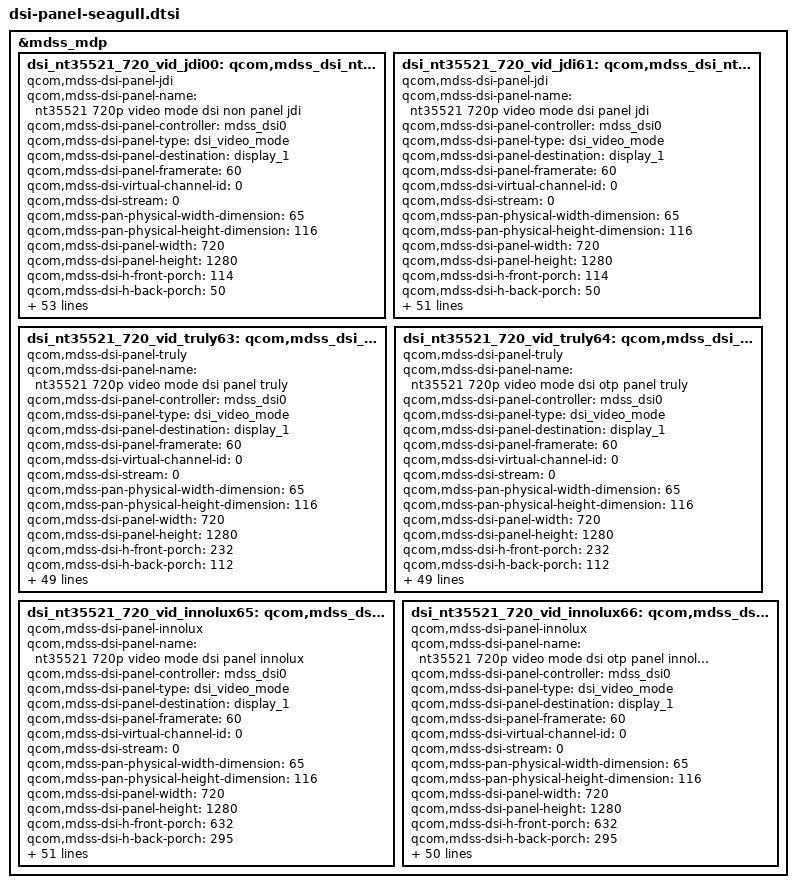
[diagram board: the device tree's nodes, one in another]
/* Copyright (c) 2013, The Linux Foundation. All rights reserved.
 *
 * This program is free software; you can redistribute it and/or modify
 * it under the terms of the GNU General Public License version 2 and
 * only version 2 as published by the Free Software Foundation.
 *
 * This program is distributed in the hope that it will be useful,
 * but WITHOUT ANY WARRANTY; without even the implied warranty of
 * MERCHANTABILITY or FITNESS FOR A PARTICULAR PURPOSE.  See the
 * GNU General Public License for more details.
 */

/*---------------------------------------------------------------------------
 * This file is autogenerated file using gcdb parser. Please do not edit it.
 * Update input XML file to add a new entry or update variable in this file
 * VERSION = "1.0"
 *---------------------------------------------------------------------------*/
&mdss_mdp {
	dsi_nt35521_720_vid_jdi00: qcom,mdss_dsi_nt35521_720p_video_jdi00 {
		compatible = "qcom,mdss-dsi-panel-jdi";
		qcom,mdss-dsi-panel-name = "nt35521 720p video mode dsi non panel jdi";
		qcom,mdss-dsi-panel-controller = <&mdss_dsi0>;
		qcom,mdss-dsi-panel-type = "dsi_video_mode";
		qcom,mdss-dsi-panel-destination = "display_1";
		qcom,mdss-dsi-panel-framerate = <60>;
		qcom,mdss-dsi-virtual-channel-id = <0>;
		qcom,mdss-dsi-stream = <0>;
		qcom,mdss-pan-physical-width-dimension = <65>;
		qcom,mdss-pan-physical-height-dimension = <116>;
		qcom,mdss-dsi-panel-width = <720>;
		qcom,mdss-dsi-panel-height = <1280>;
		qcom,mdss-dsi-h-front-porch = <114>;
		qcom,mdss-dsi-h-back-porch = <50>;
		qcom,mdss-dsi-h-pulse-width = <10>;
		qcom,mdss-dsi-h-sync-skew = <0>;
		qcom,mdss-dsi-v-back-porch = <10>;
		qcom,mdss-dsi-v-front-porch = <13>;
		qcom,mdss-dsi-v-pulse-width = <1>;
		qcom,mdss-dsi-h-left-border = <0>;
		qcom,mdss-dsi-h-right-border = <0>;
		qcom,mdss-dsi-v-top-border = <0>;
		qcom,mdss-dsi-v-bottom-border = <0>;
		qcom,mdss-dsi-bpp = <24>;
		qcom,mdss-dsi-color-order = <0>;
		qcom,mdss-dsi-underflow-color = <0xff>;
		qcom,mdss-dsi-border-color = <0>;
		qcom,mdss-dsi-pixel-packing = <0>;
		somc,mdss-dsi-id-read-command = [06 01 00 01 05 00 02 A1 00];
		qcom,mdss-dsi-on-command = [
				29 01 00 00 00 00 06 F0 55 AA 52 08 00
				23 01 00 00 00 00 02 B6 14
				29 01 00 00 00 00 05 B8 00 00 14 0A
				23 01 00 00 00 00 02 BA 00
				29 01 00 00 00 00 03 BB 63 63
				29 01 00 00 00 00 06 BD 02 7F 0D 0B 00
				29 01 00 00 00 00 04 D9 00 02 00
				29 01 00 00 00 00 06 F0 55 AA 52 00 00

				29 01 00 00 00 00 06 F0 55 AA 52 08 01
				29 01 00 00 00 00 03 B0 0D 0D
				29 01 00 00 00 00 03 B1 0D 0D
				29 01 00 00 00 00 03 B3 30 30
				29 01 00 00 00 00 03 B4 1B 1B
				29 01 00 00 00 00 03 B6 05 05
				29 01 00 00 00 00 03 B7 05 05
				29 01 00 00 00 00 03 B8 05 05
				29 01 00 00 00 00 03 B9 45 45
				29 01 00 00 00 00 03 BA 36 36
				29 01 00 00 00 00 03 BC 50 00
				29 01 00 00 00 00 03 BD 50 00
				23 01 00 00 00 00 02 BE 80
				23 01 00 00 00 00 02 BF 80
				23 01 00 00 00 00 02 C1 01
				29 01 00 00 00 00 04 C7 61 00 00
				23 01 00 00 00 00 02 CA 00
				29 01 00 00 00 00 04 CF 00 50 50
				29 01 00 00 00 00 06 F0 55 AA 52 00 00

				29 01 00 00 00 00 06 F0 55 AA 52 08 02
				29 01 00 00 00 00 11 B0 00 00 00 0F 00 29 00 3D 00 50 00 6F 00 8A 00 B6
				29 01 00 00 00 00 11 B1 00 DC 01 17 01 47 01 90 01 CB 01 CD 02 02 02 3E
				29 01 00 00 00 00 11 B2 02 71 02 B8 02 EC 03 37 03 6A 03 87 03 A0 03 A2
				29 01 00 00 00 00 05 B3 03 B6 03 CC
				29 01 00 00 00 00 11 B4 00 00 00 0F 00 29 00 3D 00 50 00 6F 00 8A 00 B6
				29 01 00 00 00 00 11 B5 00 DC 01 17 01 47 01 90 01 CB 01 CD 02 02 02 3E
				29 01 00 00 00 00 11 B6 02 71 02 B8 02 EC 03 37 03 6A 03 87 03 A0 03 A2
				29 01 00 00 00 00 05 B7 03 B6 03 CC

				29 01 00 00 00 00 11 B8 00 00 00 0F 00 29 00 3D 00 50 00 6F 00 8A 00 B6
				29 01 00 00 00 00 11 B9 00 DC 01 17 01 47 01 90 01 CB 01 CD 02 02 02 3E
				29 01 00 00 00 00 11 BA 02 71 02 B8 02 EC 03 37 03 6A 03 87 03 A0 03 A2
				29 01 00 00 00 00 05 BB 03 B6 03 CC
				29 01 00 00 00 00 11 BC 00 00 00 0F 00 29 00 3D 00 50 00 6F 00 8A 00 B6
				29 01 00 00 00 00 11 BD 00 DC 01 17 01 47 01 90 01 CB 01 CD 02 02 02 3E
				29 01 00 00 00 00 11 BE 02 71 02 B8 02 EC 03 37 03 6A 03 87 03 A0 03 A2
				29 01 00 00 00 00 05 BF 03 B7 03 CC

				29 01 00 00 00 00 11 C0 00 00 00 0F 00 29 00 3D 00 50 00 6F 00 8A 00 B6
				29 01 00 00 00 00 11 C1 00 DC 01 17 01 47 01 90 01 CB 01 CD 02 02 02 3E
				29 01 00 00 00 00 11 C2 02 71 02 B8 02 EC 03 37 03 6A 03 87 03 A0 03 A2
				29 01 00 00 00 00 05 C3 03 B6 03 CC
				29 01 00 00 00 00 11 C4 00 00 00 0F 00 29 00 3D 00 50 00 6F 00 8A 00 B6
				29 01 00 00 00 00 11 C5 00 DC 01 17 01 47 01 90 01 CB 01 CD 02 02 02 3E
				29 01 00 00 00 00 11 C6 02 71 02 B8 02 EC 03 37 03 6A 03 87 03 A0 03 A2
				29 01 00 00 00 00 05 C7 03 B6 03 CC
				23 01 00 00 00 00 02 EE 00
				29 01 00 00 00 00 06 F0 55 AA 52 00 00

				29 01 00 00 00 00 06 F0 55 AA 52 08 03
				29 01 00 00 00 00 03 B0 F5 00
				29 01 00 00 00 00 03 B1 F5 00
				29 01 00 00 00 00 06 B2 03 00 4C 00 01
				29 01 00 00 00 00 06 B6 03 00 4C 00 01
				29 01 00 00 00 00 06 BA 35 00 4C 00 01
				29 01 00 00 00 00 06 BB 35 00 4C 00 01
				29 01 00 00 00 00 05 C0 30 00 00 00
				29 01 00 00 00 00 05 C1 30 00 00 00
				29 01 00 00 00 00 05 C2 12 00 00 00
				29 01 00 00 00 00 05 C3 21 00 00 00
				23 01 00 00 00 00 02 C4 40
				29 01 00 00 00 00 06 F0 55 AA 52 00 00

				29 01 00 00 00 00 06 F0 55 AA 52 08 05
				29 01 00 00 00 00 03 B3 17 26
				29 01 00 00 00 00 03 B7 17 26
				29 01 00 00 00 00 06 BD 03 01 01 0F 0F
				23 01 00 00 00 00 02 C0 03
				23 01 00 00 00 00 02 C4 A6
				29 01 00 00 00 00 03 C8 05 30
				29 01 00 00 00 00 03 C9 01 11
				29 01 00 00 00 00 04 CC 00 00 04
				29 01 00 00 00 00 04 CD 00 00 04
				29 01 00 00 00 00 04 CE 00 00 04
				29 01 00 00 00 00 04 CF 00 00 04
				23 01 00 00 00 00 02 D0 00
				29 01 00 00 00 00 05 D1 02 00 00 04
				29 01 00 00 00 00 05 D2 02 00 00 02
				23 01 00 00 00 00 02 E5 06
				23 01 00 00 00 00 02 E6 06
				23 01 00 00 00 00 02 E7 06
				23 01 00 00 00 00 02 E8 06
				23 01 00 00 00 00 02 EC 06
				29 01 00 00 00 00 06 F0 55 AA 52 00 00

				29 01 00 00 00 00 06 F0 55 AA 52 08 06
				29 01 00 00 00 00 03 B0 2E 00
				29 01 00 00 00 00 03 B1 08 10
				29 01 00 00 00 00 03 B2 12 14
				29 01 00 00 00 00 03 B3 16 31
				29 01 00 00 00 00 03 B4 31 31
				29 01 00 00 00 00 03 B5 31 31
				29 01 00 00 00 00 03 B6 31 34
				29 01 00 00 00 00 03 B7 2B 2A
				29 01 00 00 00 00 03 B8 34 2C
				29 01 00 00 00 00 03 B9 29 34
				29 01 00 00 00 00 03 BA 34 29
				29 01 00 00 00 00 03 BB 2C 34
				29 01 00 00 00 00 03 BC 2A 2B
				29 01 00 00 00 00 03 BD 34 31
				29 01 00 00 00 00 03 BE 31 31
				29 01 00 00 00 00 03 BF 31 31
				29 01 00 00 00 00 03 C0 31 17
				29 01 00 00 00 00 03 C1 15 13
				29 01 00 00 00 00 03 C2 11 09
				29 01 00 00 00 00 03 C3 01 2E

				29 01 00 00 00 00 03 C4 2E 2D
				29 01 00 00 00 00 03 C5 01 17
				29 01 00 00 00 00 03 C6 15 13
				29 01 00 00 00 00 03 C7 11 31
				29 01 00 00 00 00 03 C8 31 31
				29 01 00 00 00 00 03 C9 31 31
				29 01 00 00 00 00 03 CA 31 34
				29 01 00 00 00 00 03 CB 2B 2A
				29 01 00 00 00 00 03 CC 34 2C
				29 01 00 00 00 00 03 CD 29 34
				29 01 00 00 00 00 03 CE 34 29
				29 01 00 00 00 00 03 CF 2C 34
				29 01 00 00 00 00 03 D0 2A 2B
				29 01 00 00 00 00 03 D1 34 31
				29 01 00 00 00 00 03 D2 31 31
				29 01 00 00 00 00 03 D3 31 31
				29 01 00 00 00 00 03 D4 31 10
				29 01 00 00 00 00 03 D5 12 14
				29 01 00 00 00 00 03 D6 16 00
				29 01 00 00 00 00 03 D7 2D 2E

				29 01 00 00 00 00 06 D8 00 00 00 00 00
				29 01 00 00 00 00 06 D9 00 00 00 00 00
				29 01 00 00 00 00 03 E5 34 34
				29 01 00 00 00 00 03 E6 34 34
				23 01 00 00 00 00 02 E7 00
				29 01 00 00 00 00 06 F0 55 AA 52 00 00

				//Modify backlight leds's freq to 65.1kHz
				29 01 00 00 00 00 06 F0 55 AA 52 08 00
				29 01 00 00 00 00 04 D9 02 03 00
				29 01 00 00 00 00 06 F0 55 AA 52 00 00

				/*Disable HS mode MIPI can receive command that is avoid ESD issue*/
				29 01 00 00 00 00 06 F0 55 AA 52 08 00
				29 01 00 00 00 00 03 B1 6C 21
				29 01 00 00 00 00 06 F0 55 AA 52 00 00
				29 01 00 00 00 00 02 35 00

				05 01 00 00 78 00 02 11 00
				05 01 00 00 01 00 02 29 00
				29 01 00 00 00 00 02 53 24
		];
		qcom,mdss-dsi-off-command = [05 01 00 00 32 00 02 28 00
					05 01 00 00 96 00 02 10 00];
		qcom,mdss-dsi-on-command-state = "dsi_lp_mode";
		qcom,mdss-dsi-off-command-state = "dsi_hs_mode";
		qcom,mdss-dsi-h-sync-pulse = <1>;
		qcom,mdss-dsi-traffic-mode = <2>;
		qcom,mdss-dsi-lane-map = <0>;
		qcom,mdss-dsi-bllp-eof-power-mode;
		qcom,mdss-dsi-bllp-power-mode;
		qcom,mdss-dsi-lane-0-state;
		qcom,mdss-dsi-lane-1-state;
		qcom,mdss-dsi-lane-2-state;
		qcom,mdss-dsi-lane-3-state;
		qcom,mdss-dsi-panel-timings = [93 1F 17 00 2F 2E 1C 21 26 03 04 00];
		qcom,mdss-dsi-t-clk-post = <0x20>;
		qcom,mdss-dsi-t-clk-pre = <0x2D>;
		qcom,mdss-dsi-bl-min-level = <1>;
		qcom,mdss-dsi-bl-max-level = <255>;
		qcom,mdss-dsi-dma-trigger = <4>;
		qcom,mdss-dsi-mdp-trigger = <0>;
		qcom,mdss-dsi-bl-pmic-control-type = "bl_ctrl_dcs";
		qcom,platform-reset-gpio = <&msmgpio 25 0>;
		qcom,mdss-dsi-reset-sequence = <1 150>;
		somc,panel-id = [ff];
		somc,pwr-positive5-gpio = <&msmgpio 2 0>;
		somc,pwr-negative5-gpio = <&msmgpio 3 0>;
		somc,driver-ic = <4>;
		somc,panel-detect = <1>;
		somc,panel-id-read-cmds;
		somc,alt-panelid-cmd;
		somc,dsi-restart-hack;
		somc,no-vsn-gpio;
		somc,no-vsp-gpio;
	};

	dsi_nt35521_720_vid_jdi61: qcom,mdss_dsi_nt35521_720p_video_jdi61 {
		compatible = "qcom,mdss-dsi-panel-jdi";
		qcom,mdss-dsi-panel-name = "nt35521 720p video mode dsi panel jdi";
		qcom,mdss-dsi-panel-controller = <&mdss_dsi0>;
		qcom,mdss-dsi-panel-type = "dsi_video_mode";
		qcom,mdss-dsi-panel-destination = "display_1";
		qcom,mdss-dsi-panel-framerate = <60>;
		qcom,mdss-dsi-virtual-channel-id = <0>;
		qcom,mdss-dsi-stream = <0>;
		qcom,mdss-pan-physical-width-dimension = <65>;
		qcom,mdss-pan-physical-height-dimension = <116>;
		qcom,mdss-dsi-panel-width = <720>;
		qcom,mdss-dsi-panel-height = <1280>;
		qcom,mdss-dsi-h-front-porch = <114>;
		qcom,mdss-dsi-h-back-porch = <50>;
		qcom,mdss-dsi-h-pulse-width = <10>;
		qcom,mdss-dsi-h-sync-skew = <0>;
		qcom,mdss-dsi-v-back-porch = <10>;
		qcom,mdss-dsi-v-front-porch = <13>;
		qcom,mdss-dsi-v-pulse-width = <1>;
		qcom,mdss-dsi-h-left-border = <0>;
		qcom,mdss-dsi-h-right-border = <0>;
		qcom,mdss-dsi-v-top-border = <0>;
		qcom,mdss-dsi-v-bottom-border = <0>;
		qcom,mdss-dsi-bpp = <24>;
		qcom,mdss-dsi-color-order = <0>;
		qcom,mdss-dsi-underflow-color = <0xff>;
		qcom,mdss-dsi-border-color = <0>;
		qcom,mdss-dsi-pixel-packing = <0>;
		qcom,mdss-dsi-on-command = [

				//Modify backlight leds's freq to 65.1kHz
				29 01 00 00 00 00 06 F0 55 AA 52 08 00
				29 01 00 00 00 00 04 D9 02 03 00
				29 01 00 00 00 00 06 F0 55 AA 52 00 00

				/*Disable HS mode MIPI can receive command that is avoid ESD issue*/
				29 01 00 00 00 00 06 F0 55 AA 52 08 00
				29 01 00 00 00 00 03 B1 6C 21
				29 01 00 00 00 00 06 F0 55 AA 52 00 00
				29 01 00 00 00 00 02 35 00

				05 01 00 00 78 00 02 11 00
				05 01 00 00 01 00 02 29 00
				29 01 00 00 00 00 02 53 24
		];
		qcom,mdss-dsi-off-command = [05 01 00 00 32 00 02 28 00
					05 01 00 00 96 00 02 10 00];
		qcom,mdss-dsi-on-command-state = "dsi_lp_mode";
		qcom,mdss-dsi-off-command-state = "dsi_hs_mode";
		qcom,mdss-dsi-h-sync-pulse = <1>;
		qcom,mdss-dsi-traffic-mode = <2>;
		qcom,mdss-dsi-lane-map = <0>;
		qcom,mdss-dsi-bllp-eof-power-mode;
		qcom,mdss-dsi-bllp-power-mode;
		qcom,mdss-dsi-lane-0-state;
		qcom,mdss-dsi-lane-1-state;
		qcom,mdss-dsi-lane-2-state;
		qcom,mdss-dsi-lane-3-state;
		qcom,mdss-dsi-panel-timings = [93 1F 17 00 2F 2E 1C 21 26 03 04 00];
		qcom,mdss-dsi-t-clk-post = <0x20>;
		qcom,mdss-dsi-t-clk-pre = <0x2D>;
		qcom,mdss-dsi-bl-min-level = <1>;
		qcom,mdss-dsi-bl-max-level = <255>;
		qcom,mdss-dsi-dma-trigger = <4>;
		qcom,mdss-dsi-mdp-trigger = <0>;
		qcom,mdss-dsi-bl-pmic-control-type = "bl_ctrl_dcs";
		qcom,platform-reset-gpio = <&msmgpio 25 0>;
		qcom,mdss-dsi-reset-sequence = <1 150>;
		somc,panel-id = [61];
		somc,pwr-positive5-gpio = <&msmgpio 2 0>;
		somc,pwr-negative5-gpio = <&msmgpio 3 0>;
		somc,driver-ic = <4>;
		somc,panel-detect = <1>;
		somc,panel-id-read-cmds;
		somc,alt-panelid-cmd;
		somc,dsi-restart-hack;
		somc,no-vsn-gpio;
		somc,no-vsp-gpio;
	};

	dsi_nt35521_720_vid_truly63: qcom,mdss_dsi_nt35521_720p_video_truly63 {
		compatible = "qcom,mdss-dsi-panel-truly";
		qcom,mdss-dsi-panel-name = "nt35521 720p video mode dsi panel truly";
		qcom,mdss-dsi-panel-controller = <&mdss_dsi0>;
		qcom,mdss-dsi-panel-type = "dsi_video_mode";
		qcom,mdss-dsi-panel-destination = "display_1";
		qcom,mdss-dsi-panel-framerate = <60>;
		qcom,mdss-dsi-virtual-channel-id = <0>;
		qcom,mdss-dsi-stream = <0>;
		qcom,mdss-pan-physical-width-dimension = <65>;
		qcom,mdss-pan-physical-height-dimension = <116>;
		qcom,mdss-dsi-panel-width = <720>;
		qcom,mdss-dsi-panel-height = <1280>;

		qcom,mdss-dsi-h-front-porch = <232>; //514Mbps
		qcom,mdss-dsi-h-back-porch = <112>; //514Mbps
		qcom,mdss-dsi-h-pulse-width = <20>; //514Mbps
		qcom,mdss-dsi-h-sync-skew = <0>;
		qcom,mdss-dsi-v-back-porch = <18>;
		qcom,mdss-dsi-v-front-porch = <18>;
		qcom,mdss-dsi-v-pulse-width = <1>;

		qcom,mdss-dsi-h-left-border = <0>;
		qcom,mdss-dsi-h-right-border = <0>;
		qcom,mdss-dsi-v-top-border = <0>;
		qcom,mdss-dsi-v-bottom-border = <0>;
		qcom,mdss-dsi-bpp = <24>;
		qcom,mdss-dsi-underflow-color = <0xff>;
		qcom,mdss-dsi-border-color = <0>;
		qcom,mdss-dsi-pixel-packing = "tight";
		qcom,mdss-dsi-on-command = [
                        29 01 00 00 00 00 06 F0 55 AA 52 08 00
                        29 01 00 00 00 00 05 FF AA 55 A5 80
                        29 01 00 00 00 00 03 6F 11 00
                        29 01 00 00 00 00 03 F7 20 00
                        29 01 00 00 00 00 02 6F 01
                        29 01 00 00 00 00 02 B1 21
                        29 01 00 00 00 00 06 BD 01 A0 10 08 01
                        29 01 00 00 00 00 05 B8 01 02 0C 02
                        29 01 00 00 00 00 03 BB 11 11
                        29 01 00 00 00 00 03 BC 00 00
                        //UPDATE 0620
                        29 01 00 00 00 00 02 B6 02
                        //REGW B6 16
                        
                        29 01 00 00 00 00 06 F0 55 AA 52 08 01
                        29 01 00 00 00 00 03 B0 09 09
                        29 01 00 00 00 00 03 B1 09 09
                        
                        //VGMP=4.75V
                        29 01 00 00 00 00 03 BC 8C 00
                        29 01 00 00 00 00 03 BD 8C 00
                        29 01 00 00 00 00 02 CA 00
                        //MIPI VIDEO MODE
                        29 01 00 00 00 00 02 C0 04
                        29 01 00 00 00 00 02 BE B5
                        29 01 00 00 00 00 03 B3 35 35
                        29 01 00 00 00 00 03 B4 25 25
                        29 01 00 00 00 00 03 B9 43 43
                        29 01 00 00 00 00 03 BA 24 24
                        
                        //2013/11/14 G2.2
                        29 01 00 00 00 00 06 F0 55 AA 52 08 02
                        29 01 00 00 00 00 02 EE 03

//R(+) MCR cmd
                        29 01 00 00 00 00 11 B0 00 B2 00 B3 00 B6 00 C3 00 CE 00 E1 00 F3 01 11
                        29 01 00 00 00 00 11 B1 01 2E 01 5C 01 82 01 C3 01 FE 02 00 02 37 02 77
                        29 01 00 00 00 00 11 B2 02 A1 02 D7 02 FE 03 2C 03 4B 03 63 03 8F 03 90
                        29 01 00 00 00 00 05 B3 03 96 03 98
//G(+) MCR cmd
                        29 01 00 00 00 00 11 B4 00 81 00 8B 00 9C 00 A9 00 B5 00 CB 00 DF 01 02
                        29 01 00 00 00 00 11 B5 01 1F 01 51 01 7A 01 BF 01 FA 01 FC 02 34 02 76
                        29 01 00 00 00 00 11 B6 02 9F 02 D7 02 FC 03 2C 03 4A 03 63 03 8F 03 A2
                        29 01 00 00 00 00 05 B7 03 B8 03 BA
//B(+) MCR cmd
                        29 01 00 00 00 00 11 B8 00 01 00 02 00 0E 00 2A 00 41 00 67 00 87 00 B9
                        29 01 00 00 00 00 11 B9 00 E2 01 22 01 54 01 A3 01 E6 01 E7 02 24 02 67
                        29 01 00 00 00 00 11 BA 02 93 02 CD 02 F6 03 31 03 6C 03 E9 03 EF 03 F4
                        29 01 00 00 00 00 05 BB 03 F6 03 F7

                        
                        //TIMING SETTING
                        29 01 00 00 00 00 06 F0 55 AA 52 08 03
                        
                        29 01 00 00 00 00 03 B0 22 00
                        29 01 00 00 00 00 03 B1 22 00
                        
                        29 01 00 00 00 00 06 B2 05 00 60 00 00
                        29 01 00 00 00 00 06 B3 05 00 60 00 00
                        29 01 00 00 00 00 06 B4 05 00 60 00 00
                        29 01 00 00 00 00 06 B5 05 00 60 00 00
                        
                        29 01 00 00 00 00 06 BA 53 00 60 00 00
                        29 01 00 00 00 00 06 BB 53 00 60 00 00
                        29 01 00 00 00 00 06 BC 53 00 60 00 00
                        29 01 00 00 00 00 06 BD 53 00 60 00 00
                        
                        29 01 00 00 00 00 05 C0 00 34 00 00
                        29 01 00 00 00 00 05 C1 00 00 34 00
                        29 01 00 00 00 00 05 C2 00 00 34 00
                        29 01 00 00 00 00 05 C3 00 00 34 00
                        29 01 00 00 00 00 02 C4 60
                        29 01 00 00 00 00 02 C5 C0
                        29 01 00 00 00 00 02 C6 00
                        29 01 00 00 00 00 02 C7 00
                        
                        29 01 00 00 00 00 06 F0 55 AA 52 08 05
                        
                        29 01 00 00 00 00 03 B0 17 06
                        29 01 00 00 00 00 03 B1 17 06
                        29 01 00 00 00 00 03 B2 17 06
                        29 01 00 00 00 00 03 B3 17 06
                        29 01 00 00 00 00 03 B4 17 06
                        29 01 00 00 00 00 03 B5 17 06
                        29 01 00 00 00 00 03 B6 17 06
                        29 01 00 00 00 00 03 B7 17 06
                        29 01 00 00 00 00 02 B8 00
                        29 01 00 00 00 00 03 B9 00 03
                        29 01 00 00 00 00 03 BA 00 00
                        29 01 00 00 00 00 03 BB 02 03
                        29 01 00 00 00 00 03 BC 02 03
                        29 01 00 00 00 00 06 BD 03 03 00 03 03
                        29 01 00 00 00 00 02 C0 0B
                        29 01 00 00 00 00 02 C1 09
                        29 01 00 00 00 00 02 C2 A6
                        29 01 00 00 00 00 02 C3 05
                        29 01 00 00 00 00 02 C4 00
                        29 01 00 00 00 00 02 C5 02
                        29 01 00 00 00 00 02 C6 22
                        29 01 00 00 00 00 02 C7 03
                        29 01 00 00 00 00 03 C8 07 20
                        29 01 00 00 00 00 03 C9 03 20
                        29 01 00 00 00 00 03 CA 01 60
                        29 01 00 00 00 00 03 CB 01 60
                        29 01 00 00 00 00 04 CC 00 00 02
                        29 01 00 00 00 00 04 CD 00 00 02
                        29 01 00 00 00 00 04 CE 00 00 02
                        29 01 00 00 00 00 04 CF 00 00 02
                        29 01 00 00 00 00 06 D1 00 05 01 07 10
                        29 01 00 00 00 00 06 D2 10 05 05 03 10
                        29 01 00 00 00 00 06 D3 20 00 43 07 10
                        29 01 00 00 00 00 06 D4 30 00 43 07 10
                        29 01 00 00 00 00 08 D0 00 00 00 00 00 00 00
                        29 01 00 00 00 00 0C D5 00 00 00 00 00 00 00 00 00 00 00
                        29 01 00 00 00 00 0C D6 00 00 00 00 00 00 00 00 00 00 00
                        29 01 00 00 00 00 0C D7 00 00 00 00 00 00 00 00 00 00 00
                        29 01 00 00 00 00 06 D8 00 00 00 00 00
                        29 01 00 00 00 00 02 E5 06
                        29 01 00 00 00 00 02 E6 06
                        29 01 00 00 00 00 02 E7 00
                        29 01 00 00 00 00 02 E8 06
                        29 01 00 00 00 00 02 E9 06
                        29 01 00 00 00 00 02 EA 06
                        29 01 00 00 00 00 02 EB 00
                        29 01 00 00 00 00 02 EC 00
                        29 01 00 00 00 00 02 ED 30
                        
                        29 01 00 00 00 00 06 F0 55 AA 52 08 06
                        
                        29 01 00 00 00 00 03 B0 31 31
                        29 01 00 00 00 00 03 B1 31 31
                        29 01 00 00 00 00 03 B2 2D 2E
                        29 01 00 00 00 00 03 B3 31 34
                        29 01 00 00 00 00 03 B4 29 2A
                        29 01 00 00 00 00 03 B5 12 10
                        29 01 00 00 00 00 03 B6 18 16
                        29 01 00 00 00 00 03 B7 00 02
                        29 01 00 00 00 00 03 B8 08 31
                        29 01 00 00 00 00 03 B9 31 31
                        
                        29 01 00 00 00 00 03 BA 31 31
                        29 01 00 00 00 00 03 BB 31 08
                        29 01 00 00 00 00 03 BC 03 01
                        29 01 00 00 00 00 03 BD 17 19
                        29 01 00 00 00 00 03 BE 11 13
                        29 01 00 00 00 00 03 BF 2A 29
                        29 01 00 00 00 00 03 C0 34 31
                        29 01 00 00 00 00 03 C1 2E 2D
                        29 01 00 00 00 00 03 C2 31 31
                        29 01 00 00 00 00 03 C3 31 31
                        
                        29 01 00 00 00 00 03 C4 31 31
                        29 01 00 00 00 00 03 C5 31 31
                        29 01 00 00 00 00 03 C6 2E 2D
                        29 01 00 00 00 00 03 C7 31 34
                        29 01 00 00 00 00 03 C8 29 2A
                        29 01 00 00 00 00 03 C9 17 19
                        29 01 00 00 00 00 03 CA 11 13
                        29 01 00 00 00 00 03 CB 03 01
                        29 01 00 00 00 00 03 CC 08 31
                        29 01 00 00 00 00 03 CD 31 31
                        
                        29 01 00 00 00 00 03 CE 31 31
                        29 01 00 00 00 00 03 CF 31 08
                        29 01 00 00 00 00 03 D0 00 02
                        29 01 00 00 00 00 03 D1 12 10
                        29 01 00 00 00 00 03 D2 18 16
                        29 01 00 00 00 00 03 D3 2A 29
                        29 01 00 00 00 00 03 D4 34 31
                        29 01 00 00 00 00 03 D5 2D 2E
                        29 01 00 00 00 00 03 D6 31 31
                        29 01 00 00 00 00 03 D7 31 31
                        
                        29 01 00 00 00 00 03 E5 31 31
                        29 01 00 00 00 00 03 E6 31 31
                        
                        29 01 00 00 00 00 06 D8 00 00 00 00 00
                        29 01 00 00 00 00 06 D9 00 00 00 00 00
                        29 01 00 00 00 00 02 E7 00
                        
                        29 01 00 00 00 00 02 6F 02
                        29 01 00 00 00 00 02 F7 47
                        29 01 00 00 00 00 02 6F 0A
                        29 01 00 00 00 00 02 F7 02
                        29 01 00 00 00 00 02 6F 17
                        29 01 00 00 00 00 02 F4 60
                        
                        29 01 00 00 00 00 02 6F 01
                        29 01 00 00 00 00 02 F9 46
                        29 01 00 00 00 00 02 6F 11
                        29 01 00 00 00 00 02 F3 01
                        
                        29 01 00 00 00 00 02 35 00
                        
                        //CCMOFF
                        //CCMRUN
                        //Modify backlight leds's freq to 65.1kHz
                        29 01 00 00 00 00 06 F0 55 AA 52 08 00
                        29 01 00 00 00 00 04 D9 02 03 00
                        29 01 00 00 00 00 06 F0 55 AA 52 00 00

                        /*Disable HS mode MIPI can revice command for fix ESD isse*/
                        29 01 00 00 00 00 06 F0 55 AA 52 08 00
                        29 01 00 00 00 00 03 B1 6C 21
                        29 01 00 00 00 00 06 F0 55 AA 52 00 00
                        29 01 00 00 00 00 02 35 00

                        05 01 00 00 78 00 02 11 00
                        05 01 00 00 01 00 02 29 00
                        29 01 00 00 00 00 02 53 24

		];
		qcom,mdss-dsi-off-command = [05 01 00 00 32 00 02 28 00
					05 01 00 00 96 00 02 10 00];
		qcom,mdss-dsi-on-command-state = "dsi_lp_mode";
		qcom,mdss-dsi-off-command-state = "dsi_hs_mode";
		qcom,mdss-dsi-h-sync-pulse = <1>;
		qcom,mdss-dsi-traffic-mode = "burst_mode";
		qcom,mdss-dsi-bllp-eof-power-mode;
		qcom,mdss-dsi-bllp-power-mode;
		qcom,mdss-dsi-lane-0-state;
		qcom,mdss-dsi-lane-1-state;
		qcom,mdss-dsi-lane-2-state;
		qcom,mdss-dsi-lane-3-state;
		qcom,mdss-dsi-panel-timings = [94 20 14 00 46 4A 1A 24 18 03 04 00]; //514Mbps
		qcom,mdss-dsi-t-clk-post = <0x20>;
		qcom,mdss-dsi-t-clk-pre = <0x2D>;
		qcom,mdss-dsi-bl-min-level = <1>;
		qcom,mdss-dsi-bl-max-level = <255>;
		qcom,mdss-dsi-dma-trigger = "trigger_sw";
		qcom,mdss-dsi-mdp-trigger = "none";
		qcom,mdss-dsi-bl-pmic-control-type = "bl_ctrl_dcs";
		qcom,platform-reset-gpio = <&msmgpio 25 0>;
		qcom,mdss-dsi-reset-sequence = <1 150>;
		somc,panel-id = [63];
		somc,pwr-positive5-gpio = <&msmgpio 2 0>;
		somc,pwr-negative5-gpio = <&msmgpio 3 0>;
		somc,driver-ic = <4>;
		somc,panel-detect = <1>;
		somc,panel-id-read-cmds;
		somc,alt-panelid-cmd;
		somc,dsi-restart-hack;
		somc,no-vsn-gpio;
		somc,no-vsp-gpio;
	};

	dsi_nt35521_720_vid_truly64: qcom,mdss_dsi_nt35521_720p_video_truly64 {
		compatible = "qcom,mdss-dsi-panel-truly";
		qcom,mdss-dsi-panel-name = "nt35521 720p video mode dsi otp panel truly";
		qcom,mdss-dsi-panel-controller = <&mdss_dsi0>;
		qcom,mdss-dsi-panel-type = "dsi_video_mode";
		qcom,mdss-dsi-panel-destination = "display_1";
		qcom,mdss-dsi-panel-framerate = <60>;
		qcom,mdss-dsi-virtual-channel-id = <0>;
		qcom,mdss-dsi-stream = <0>;
		qcom,mdss-pan-physical-width-dimension = <65>;
		qcom,mdss-pan-physical-height-dimension = <116>;
		qcom,mdss-dsi-panel-width = <720>;
		qcom,mdss-dsi-panel-height = <1280>;

		qcom,mdss-dsi-h-front-porch = <232>; //514Mbps
		qcom,mdss-dsi-h-back-porch = <112>; //514Mbps
		qcom,mdss-dsi-h-pulse-width = <20>; //514Mbps
		qcom,mdss-dsi-h-sync-skew = <0>;
		qcom,mdss-dsi-v-back-porch = <18>;
		qcom,mdss-dsi-v-front-porch = <18>;
		qcom,mdss-dsi-v-pulse-width = <1>;

		qcom,mdss-dsi-h-left-border = <0>;
		qcom,mdss-dsi-h-right-border = <0>;
		qcom,mdss-dsi-v-top-border = <0>;
		qcom,mdss-dsi-v-bottom-border = <0>;
		qcom,mdss-dsi-bpp = <24>;
		qcom,mdss-dsi-underflow-color = <0xff>;
		qcom,mdss-dsi-border-color = <0>;
		qcom,mdss-dsi-pixel-packing = "tight";
		qcom,mdss-dsi-on-command = [

				//Modify backlight leds's freq to 65.1kHz
				29 01 00 00 00 00 06 F0 55 AA 52 08 00
				29 01 00 00 00 00 04 D9 02 03 00
				29 01 00 00 00 00 06 F0 55 AA 52 00 00

				/*Disable HS mode MIPI can receive command that is avoid ESD issue*/
				29 01 00 00 00 00 06 F0 55 AA 52 08 00
				29 01 00 00 00 00 03 B1 6C 21
				29 01 00 00 00 00 06 F0 55 AA 52 00 00
				29 01 00 00 00 00 02 35 00

				05 01 00 00 78 00 02 11 00
				05 01 00 00 01 00 02 29 00
				29 01 00 00 00 00 02 53 24
		];
		qcom,mdss-dsi-off-command = [05 01 00 00 32 00 02 28 00
					05 01 00 00 96 00 02 10 00];
		qcom,mdss-dsi-on-command-state = "dsi_lp_mode";
		qcom,mdss-dsi-off-command-state = "dsi_hs_mode";
		qcom,mdss-dsi-h-sync-pulse = <1>;
		qcom,mdss-dsi-traffic-mode = "burst_mode";
		qcom,mdss-dsi-bllp-eof-power-mode;
		qcom,mdss-dsi-bllp-power-mode;
		qcom,mdss-dsi-lane-0-state;
		qcom,mdss-dsi-lane-1-state;
		qcom,mdss-dsi-lane-2-state;
		qcom,mdss-dsi-lane-3-state;
		qcom,mdss-dsi-panel-timings = [94 20 14 00 46 4A 1A 24 18 03 04 00]; //514Mbsp
		qcom,mdss-dsi-t-clk-post = <0x20>;
		qcom,mdss-dsi-t-clk-pre = <0x2D>;
		qcom,mdss-dsi-bl-min-level = <1>;
		qcom,mdss-dsi-bl-max-level = <255>;
		qcom,mdss-dsi-dma-trigger = "trigger_sw";
		qcom,mdss-dsi-mdp-trigger = "none";
		qcom,mdss-dsi-bl-pmic-control-type = "bl_ctrl_dcs";
		qcom,platform-reset-gpio = <&msmgpio 25 0>;
		qcom,mdss-dsi-reset-sequence = <1 150>;
		somc,panel-id = [64];
		somc,pwr-positive5-gpio = <&msmgpio 2 0>;
		somc,pwr-negative5-gpio = <&msmgpio 3 0>;
		somc,driver-ic = <4>;
		somc,panel-detect = <1>;
		somc,panel-id-read-cmds;
		somc,alt-panelid-cmd;
		somc,dsi-restart-hack;
		somc,no-vsn-gpio;
		somc,no-vsp-gpio;
	};

	dsi_nt35521_720_vid_innolux65: qcom,mdss_dsi_nt35521_720p_video_innolux65 {
		compatible = "qcom,mdss-dsi-panel-innolux";
		qcom,mdss-dsi-panel-name = "nt35521 720p video mode dsi panel innolux";
		qcom,mdss-dsi-panel-controller = <&mdss_dsi0>;
		qcom,mdss-dsi-panel-type = "dsi_video_mode";
		qcom,mdss-dsi-panel-destination = "display_1";
		qcom,mdss-dsi-panel-framerate = <60>;
		qcom,mdss-dsi-virtual-channel-id = <0>;
		qcom,mdss-dsi-stream = <0>;
		qcom,mdss-pan-physical-width-dimension = <65>;
		qcom,mdss-pan-physical-height-dimension = <116>;
		qcom,mdss-dsi-panel-width = <720>;
		qcom,mdss-dsi-panel-height = <1280>;
		qcom,mdss-dsi-h-front-porch = <632>; //800Mbps
		qcom,mdss-dsi-h-back-porch = <295>; //800Mbps
		qcom,mdss-dsi-h-pulse-width = <40>; //800Mbps
		qcom,mdss-dsi-h-sync-skew = <0>;
		qcom,mdss-dsi-v-back-porch = <18>;
		qcom,mdss-dsi-v-front-porch = <18>;
		qcom,mdss-dsi-v-pulse-width = <1>;
		qcom,mdss-dsi-h-left-border = <0>;
		qcom,mdss-dsi-h-right-border = <0>;
		qcom,mdss-dsi-v-top-border = <0>;
		qcom,mdss-dsi-v-bottom-border = <0>;
		qcom,mdss-dsi-bpp = <24>;
		qcom,mdss-dsi-color-order = <0>;
		qcom,mdss-dsi-underflow-color = <0xff>;
		qcom,mdss-dsi-border-color = <0>;
		qcom,mdss-dsi-pixel-packing = <0>;
		qcom,mdss-dsi-on-command = [

		//Date:20140221
						29 01 00 00 00 00 05 FF AA 55 A5 80
						29 01 00 00 00 00 03 6F 11 00
						29 01 00 00 00 00 03 F7 20 00
						29 01 00 00 00 00 02 6F 06
						29 01 00 00 00 00 02 F7 A0
						29 01 00 00 00 00 02 6F 19
						29 01 00 00 00 00 02 F7 12
		
						29 01 00 00 00 00 06 F0 55 AA 52 08 00
						29 01 00 00 00 00 02 C8 83
		
						29 01 00 00 00 00 03 B1 6C 21
		
						29 01 00 00 00 00 02 B6 08
		
						29 01 00 00 00 00 02 6F 02
						29 01 00 00 00 00 02 B8 08
		
						29 01 00 00 00 00 03 BB 74 44
		
						29 01 00 00 00 00 03 BC 00 00
		
						29 01 00 00 00 00 06 BD 01 AC 10 10 01
		
						29 01 00 00 00 00 03 C5 01 07
		
						29 01 00 00 00 00 06 F0 55 AA 52 08 01
		
						29 01 00 00 00 00 03 B0 05 05
						29 01 00 00 00 00 03 B1 05 05
		
						29 01 00 00 00 00 03 BC A0 01
						29 01 00 00 00 00 03 BD A0 01
		
						29 01 00 00 00 00 02 CA 00
		
						29 01 00 00 00 00 02 C0 04
		
						29 01 00 00 00 00 02 BE 51
		
						29 01 00 00 00 00 03 B3 37 37
						29 01 00 00 00 00 03 B4 0F 0F
		
						29 01 00 00 00 00 03 B9 46 46
						29 01 00 00 00 00 03 BA 24 24
						//=======================================Page2
						29 01 00 00 00 00 06 F0 55 AA 52 08 02
		
						29 01 00 00 00 00 02 EE 01
						29 01 00 00 00 00 05 EF 09 06 15 18
		
						29 01 00 00 00 00 07 B0 00 00 00 1D 00 46
						29 01 00 00 00 00 02 6F 06
						29 01 00 00 00 00 07 B0 00 5C 00 71 00 9F
						29 01 00 00 00 00 02 6F 0C
						29 01 00 00 00 00 05 B0 00 C6 01 00
						29 01 00 00 00 00 07 B1 01 30 01 78 01 B2
						29 01 00 00 00 00 02 6F 06
						29 01 00 00 00 00 07 B1 02 0C 02 53 02 55
						29 01 00 00 00 00 02 6F 0C
						29 01 00 00 00 00 05 B1 02 98 02 E4
						29 01 00 00 00 00 07 B2 03 0D 03 4B 03 7C
						29 01 00 00 00 00 02 6F 06
						29 01 00 00 00 00 07 B2 03 9D 03 B7 03 D0
						29 01 00 00 00 00 02 6F 0C
						29 01 00 00 00 00 05 B2 03 DE 03 E2
						29 01 00 00 00 00 05 B3 03 F0 03 F2
						//=======================================Page2
		
						29 01 00 00 00 00 06 F0 55 AA 52 08 06
						29 01 00 00 00 00 03 B0 29 2A
						29 01 00 00 00 00 03 B1 10 12
						29 01 00 00 00 00 03 B2 14 16
						29 01 00 00 00 00 03 B3 18 1A
						29 01 00 00 00 00 03 B4 08 0A
						29 01 00 00 00 00 03 B5 2E 2E
						29 01 00 00 00 00 03 B6 2E 2E
						29 01 00 00 00 00 03 B7 2E 2E
						29 01 00 00 00 00 03 B8 2E 00
						29 01 00 00 00 00 03 B9 2E 2E
						29 01 00 00 00 00 03 BA 2E 2E
						29 01 00 00 00 00 03 BB 01 2E
						29 01 00 00 00 00 03 BC 2E 2E
						29 01 00 00 00 00 03 BD 2E 2E
						29 01 00 00 00 00 03 BE 2E 2E
						29 01 00 00 00 00 03 BF 0B 09
						29 01 00 00 00 00 03 C0 1B 19
						29 01 00 00 00 00 03 C1 17 15
						29 01 00 00 00 00 03 C2 13 11
						29 01 00 00 00 00 03 C3 2A 29
						29 01 00 00 00 00 03 E5 2E 2E
		
						29 01 00 00 00 00 03 C4 29 2A
						29 01 00 00 00 00 03 C5 1B 19
						29 01 00 00 00 00 03 C6 17 15
						29 01 00 00 00 00 03 C7 13 11
						29 01 00 00 00 00 03 C8 01 0B
						29 01 00 00 00 00 03 C9 2E 2E
						29 01 00 00 00 00 03 CA 2E 2E
						29 01 00 00 00 00 03 CB 2E 2E
						29 01 00 00 00 00 03 CC 2E 09
						29 01 00 00 00 00 03 CD 2E 2E
						29 01 00 00 00 00 03 CE 2E 2E
						29 01 00 00 00 00 03 CF 08 2E
						29 01 00 00 00 00 03 D0 2E 2E
						29 01 00 00 00 00 03 D1 2E 2E
						29 01 00 00 00 00 03 D2 2E 2E
						29 01 00 00 00 00 03 D3 0A 00
						29 01 00 00 00 00 03 D4 10 12
						29 01 00 00 00 00 03 D5 14 16
						29 01 00 00 00 00 03 D6 18 1A
						29 01 00 00 00 00 03 D7 2A 29
						29 01 00 00 00 00 03 E6 2E 2E
						29 01 00 00 00 00 06 D8 00 00 00 00 00
						29 01 00 00 00 00 06 D9 00 00 00 00 00
						29 01 00 00 00 00 02 E7 00
		
						29 01 00 00 00 00 06 F0 55 AA 52 08 03
						29 01 00 00 00 00 03 B0 00 00
						29 01 00 00 00 00 03 B1 00 00
						29 01 00 00 00 00 06 B2 05 00 00 00 00
		
						29 01 00 00 00 00 06 B6 05 00 00 00 00
						29 01 00 00 00 00 06 B7 05 00 00 00 00
		
						29 01 00 00 00 00 06 BA 57 00 00 00 00
						29 01 00 00 00 00 06 BB 57 00 00 00 00
		
						29 01 00 00 00 00 05 C0 00 00 00 00
						29 01 00 00 00 00 05 C1 00 00 00 00
		
						29 01 00 00 00 00 02 C4 60
						29 01 00 00 00 00 02 C5 40
		
						29 01 00 00 00 00 06 F0 55 AA 52 08 05
						29 01 00 00 00 00 06 BD 03 01 03 03 03
						29 01 00 00 00 00 03 B0 17 06
						29 01 00 00 00 00 03 B1 17 06
						29 01 00 00 00 00 03 B2 17 06
						29 01 00 00 00 00 03 B3 17 06
						29 01 00 00 00 00 03 B4 17 06
						29 01 00 00 00 00 03 B5 17 06
		
						29 01 00 00 00 00 02 B8 00
						29 01 00 00 00 00 02 B9 00
						29 01 00 00 00 00 02 BA 00
						29 01 00 00 00 00 02 BB 02
						29 01 00 00 00 00 02 BC 00
		
						29 01 00 00 00 00 02 C0 07
		
						29 01 00 00 00 00 02 C4 80
						29 01 00 00 00 00 02 C5 A4
		
						29 01 00 00 00 00 03 C8 05 30
						29 01 00 00 00 00 03 C9 01 31
		
						29 01 00 00 00 00 04 CC 00 00 3C
						29 01 00 00 00 00 04 CD 00 00 3C
		
						29 01 00 00 00 00 06 D1 00 05 09 07 10
						29 01 00 00 00 00 06 D2 00 05 0E 07 10
		
						29 01 00 00 00 00 02 E5 06
						29 01 00 00 00 00 02 E6 06
						29 01 00 00 00 00 02 E7 06
						29 01 00 00 00 00 02 E8 06
						29 01 00 00 00 00 02 E9 06
						29 01 00 00 00 00 02 EA 06
		
						29 01 00 00 00 00 02 ED 30
		
						29 01 00 00 00 00 02 6F 11
						29 01 00 00 00 00 02 F3 01
		
						29 01 00 00 00 00 02 35 00

                //Modify backlight leds's freq to 65.1kHz
                29 01 00 00 00 00 06 F0 55 AA 52 08 00
                29 01 00 00 00 00 04 D9 02 03 00
                29 01 00 00 00 00 06 F0 55 AA 52 00 00
                
                /*Disable HS mode MIPI can revice command for fix ESD isse*/
                29 01 00 00 00 00 06 F0 55 AA 52 08 00
                29 01 00 00 00 00 03 B1 6C 21
                29 01 00 00 00 00 06 F0 55 AA 52 00 00
                29 01 00 00 00 00 02 35 00

                05 01 00 00 78 00 02 11 00
                05 01 00 00 00 00 02 29 00
                29 01 00 00 00 00 02 53 24
		];
		qcom,mdss-dsi-off-command = [05 01 00 00 32 00 02 28 00
					05 01 00 00 96 00 02 10 00];
		qcom,mdss-dsi-on-command-state = "dsi_lp_mode";
		qcom,mdss-dsi-off-command-state = "dsi_hs_mode";
		qcom,mdss-dsi-h-sync-pulse = <1>;
		qcom,mdss-dsi-traffic-mode = <2>;
		qcom,mdss-dsi-lane-map = <0>;
		qcom,mdss-dsi-bllp-eof-power-mode;
		qcom,mdss-dsi-bllp-power-mode;
		qcom,mdss-dsi-lane-0-state;
		qcom,mdss-dsi-lane-1-state;
		qcom,mdss-dsi-lane-2-state;
		qcom,mdss-dsi-lane-3-state;
//		qcom,mdss-dsi-panel-timings = [93 1F 17 00 2F 2E 1C 21 26 03 04 00]; //420Mbps
		qcom,mdss-dsi-panel-timings =[D5 32 22 00 60 64 26 34 29 03 04 00];//800Mbsp
		qcom,mdss-dsi-t-clk-post = <0x20>;
		qcom,mdss-dsi-t-clk-pre = <0x2D>;
		qcom,mdss-dsi-bl-min-level = <1>;
		qcom,mdss-dsi-bl-max-level = <255>;
		qcom,mdss-dsi-dma-trigger = <4>;
		qcom,mdss-dsi-mdp-trigger = <0>;
		qcom,mdss-dsi-bl-pmic-control-type = "bl_ctrl_dcs";
		qcom,platform-reset-gpio = <&msmgpio 25 0>;
		qcom,mdss-dsi-reset-sequence = <1 150>;
		somc,panel-id = [65];
		somc,pwr-positive5-gpio = <&msmgpio 2 0>;
		somc,pwr-negative5-gpio = <&msmgpio 3 0>;
		somc,driver-ic = <4>;
		somc,alt-panelid-cmd;
		somc,dsi-restart-hack;
		somc,panel-detect = <1>;
		somc,panel-id-read-cmds;
		somc,no-vsn-gpio;
		somc,no-vsp-gpio;
	};

	dsi_nt35521_720_vid_innolux66: qcom,mdss_dsi_nt35521_720p_video_innolux66 {
		compatible = "qcom,mdss-dsi-panel-innolux";
		qcom,mdss-dsi-panel-name = "nt35521 720p video mode dsi otp panel innolux";
		qcom,mdss-dsi-panel-controller = <&mdss_dsi0>;
		qcom,mdss-dsi-panel-type = "dsi_video_mode";
		qcom,mdss-dsi-panel-destination = "display_1";
		qcom,mdss-dsi-panel-framerate = <60>;
		qcom,mdss-dsi-virtual-channel-id = <0>;
		qcom,mdss-dsi-stream = <0>;
		qcom,mdss-pan-physical-width-dimension = <65>;
		qcom,mdss-pan-physical-height-dimension = <116>;
		qcom,mdss-dsi-panel-width = <720>;
		qcom,mdss-dsi-panel-height = <1280>;
		qcom,mdss-dsi-h-front-porch = <632>; //800Mbps
		qcom,mdss-dsi-h-back-porch = <295>; //800Mbps
		qcom,mdss-dsi-h-pulse-width = <40>; //800Mbps
		qcom,mdss-dsi-h-sync-skew = <0>;
		qcom,mdss-dsi-v-back-porch = <18>;
		qcom,mdss-dsi-v-front-porch = <18>;
		qcom,mdss-dsi-v-pulse-width = <1>;
		qcom,mdss-dsi-h-left-border = <0>;
		qcom,mdss-dsi-h-right-border = <0>;
		qcom,mdss-dsi-v-top-border = <0>;
		qcom,mdss-dsi-v-bottom-border = <0>;
		qcom,mdss-dsi-bpp = <24>;
		qcom,mdss-dsi-color-order = <0>;
		qcom,mdss-dsi-underflow-color = <0xff>;
		qcom,mdss-dsi-border-color = <0>;
		qcom,mdss-dsi-pixel-packing = <0>;
		qcom,mdss-dsi-on-command = [

				//Modify backlight leds's freq to 65.1kHz
				29 01 00 00 00 00 06 F0 55 AA 52 08 00
				29 01 00 00 00 00 04 D9 02 03 00
				29 01 00 00 00 00 06 F0 55 AA 52 00 00

				/*Disable HS mode MIPI can receive command that is avoid ESD issue*/
				29 01 00 00 00 00 06 F0 55 AA 52 08 00
				29 01 00 00 00 00 03 B1 6C 21
				29 01 00 00 00 00 06 F0 55 AA 52 00 00
				29 01 00 00 00 00 02 35 00

				05 01 00 00 78 00 02 11 00
				05 01 00 00 01 00 02 29 00
				29 01 00 00 00 00 02 53 24
		];

		qcom,mdss-dsi-off-command = [05 01 00 00 32 00 02 28 00
					05 01 00 00 96 00 02 10 00];
		qcom,mdss-dsi-on-command-state = "dsi_lp_mode";
		qcom,mdss-dsi-off-command-state = "dsi_hs_mode";
		qcom,mdss-dsi-h-sync-pulse = <1>;
		qcom,mdss-dsi-traffic-mode = <2>;
		qcom,mdss-dsi-lane-map = <0>;
		qcom,mdss-dsi-bllp-eof-power-mode;
		qcom,mdss-dsi-bllp-power-mode;
		qcom,mdss-dsi-lane-0-state;
		qcom,mdss-dsi-lane-1-state;
		qcom,mdss-dsi-lane-2-state;
		qcom,mdss-dsi-lane-3-state;
		qcom,mdss-dsi-panel-timings =[D5 32 22 00 60 64 26 34 29 03 04 00];//800Mbsp
		qcom,mdss-dsi-t-clk-post = <0x20>;
		qcom,mdss-dsi-t-clk-pre = <0x2D>;
		qcom,mdss-dsi-bl-min-level = <1>;
		qcom,mdss-dsi-bl-max-level = <255>;
		qcom,mdss-dsi-dma-trigger = <4>;
		qcom,mdss-dsi-mdp-trigger = <0>;
		qcom,mdss-dsi-bl-pmic-control-type = "bl_ctrl_dcs";
		qcom,platform-reset-gpio = <&msmgpio 25 0>;
		qcom,mdss-dsi-reset-sequence = <1 150>;
		somc,panel-id = [66];
		somc,pwr-positive5-gpio = <&msmgpio 2 0>;
		somc,pwr-negative5-gpio = <&msmgpio 3 0>;
		somc,driver-ic = <4>;
		somc,alt-panelid-cmd;
		somc,dsi-restart-hack;
		somc,panel-id-read-cmds;
		somc,no-vsn-gpio;
		somc,no-vsp-gpio;
	};
};
